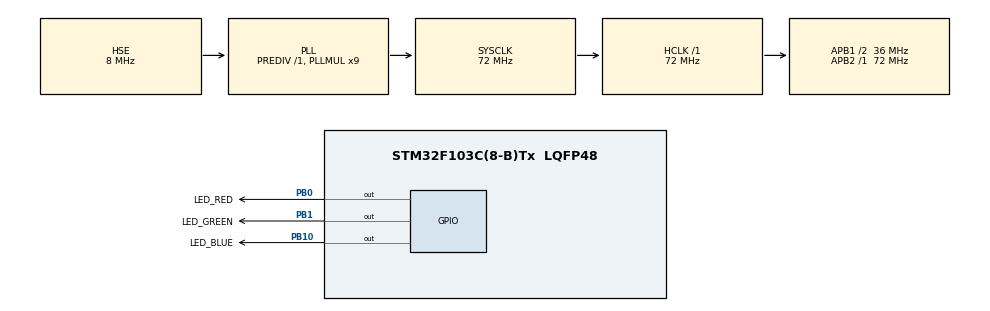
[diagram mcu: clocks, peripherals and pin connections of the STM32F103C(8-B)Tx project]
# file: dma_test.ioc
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Dma.MEMTOMEM.0.Direction=DMA_MEMORY_TO_MEMORY
Dma.MEMTOMEM.0.Instance=DMA1_Channel1
Dma.MEMTOMEM.0.MemDataAlignment=DMA_MDATAALIGN_BYTE
Dma.MEMTOMEM.0.MemInc=DMA_MINC_ENABLE
Dma.MEMTOMEM.0.Mode=DMA_NORMAL
Dma.MEMTOMEM.0.PeriphDataAlignment=DMA_PDATAALIGN_BYTE
Dma.MEMTOMEM.0.PeriphInc=DMA_PINC_ENABLE
Dma.MEMTOMEM.0.Priority=DMA_PRIORITY_LOW
Dma.Request0=MEMTOMEM
Mcu.Family=STM32F1
Mcu.Name=STM32F103C(8-B)Tx
Mcu.Package=LQFP48
NVIC.PriorityGroup=NVIC_PRIORITYGROUP_4
PA13.Mode=Serial_Wire
PA13.Signal=SYS_JTMS-SWDIO
PA14.Mode=Serial_Wire
PA14.Signal=SYS_JTCK-SWCLK
PB0.GPIO_Label=LED_RED
PB0.Signal=GPIO_Output
PB1.GPIO_Label=LED_GREEN
PB1.Signal=GPIO_Output
PB10.GPIO_Label=LED_BLUE
PB10.Signal=GPIO_Output
PD0-OSC_IN.Mode=HSE-External-Oscillator
PD0-OSC_IN.Signal=RCC_OSC_IN
PD1-OSC_OUT.Mode=HSE-External-Oscillator
PD1-OSC_OUT.Signal=RCC_OSC_OUT
ProjectManager.HeapSize=0x200
ProjectManager.StackSize=0x400
ProjectManager.TargetToolchain=CMake
RCC.AHBFreq_Value=72000000
RCC.APB1CLKDivider=RCC_HCLK_DIV2
RCC.APB1Freq_Value=36000000
RCC.APB1TimFreq_Value=72000000
RCC.APB2Freq_Value=72000000
RCC.APB2TimFreq_Value=72000000
RCC.HCLKFreq_Value=72000000
RCC.PLLMUL=RCC_PLL_MUL9
RCC.PLLSourceVirtual=RCC_PLLSOURCE_HSE
RCC.SYSCLKFreq_VALUE=72000000
RCC.SYSCLKSource=RCC_SYSCLKSOURCE_PLLCLK
RCC.USBFreq_Value=72000000
board=custom

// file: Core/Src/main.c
/* USER CODE BEGIN Header */
/**
  ******************************************************************************
  * @file           : main.c
  * @brief          : Main program body
  ******************************************************************************
  * @attention
  *
  * Copyright (c) 2025 STMicroelectronics.
  * All rights reserved.
  *
  * This software is licensed under terms that can be found in the LICENSE file
  * in the root directory of this software component.
  * If no LICENSE file comes with this software, it is provided AS-IS.
  *
  ******************************************************************************
  */
/* USER CODE END Header */
#include "main.h"
#include "dma.h"
#include "gpio.h"
#include "stm32f103xb.h"
#include "stm32f1xx_hal.h"
#include "stm32f1xx_hal_dma.h"
#include "stm32f1xx_hal_gpio.h"

/* USER CODE BEGIN Includes */

#include <stdint.h>
#include <string.h>

/* USER CODE END Includes */

/* USER CODE BEGIN PD */

#define DATA_LEN 10 // 传输数据长度

/* USER CODE END PD */

/* USER CODE BEGIN PV */

// 源数据（存于flash，用const和属性定位到只读区）
const uint8_t src_data[DATA_LEN] __attribute__((section(".rodata"))) = {0x01, 0x02, 0x03, 0x04, 0x05, 0x06, 0x07, 0x08, 0x09, 0x0A};
// 目标数据（存于SRAM）
uint8_t dest_data[DATA_LEN] = {0};

/* USER CODE END PV */

void SystemClock_Config(void);

int main(void)
{

  /* MCU Configuration--------------------------------------------------------*/

  /* Reset of all peripherals, Initializes the Flash interface and the Systick. */
  HAL_Init();

  /* Configure the system clock */
  SystemClock_Config();

  /* Initialize all configured peripherals */
  MX_GPIO_Init();
  MX_DMA_Init();
  /* USER CODE BEGIN 2 */

  // 配置dma传输参数
  HAL_DMA_Start(&hdma_memtomem_dma1_channel1, (uint32_t)src_data, (uint32_t)dest_data, DATA_LEN);

  // 等待dma传输完成
  HAL_DMA_PollForTransfer(&hdma_memtomem_dma1_channel1, HAL_DMA_FULL_TRANSFER, HAL_MAX_DELAY);

  // 数据比对
  uint8_t is_match = 1;
  for (int i = 0; i < DATA_LEN; i++) {
    if (src_data[i] != dest_data[i]) {
      is_match = 0;
      break;
    }
  }

  // RGB灯显示结果
  if (is_match) {
    // RGB彩灯亮
    HAL_GPIO_WritePin(GPIOB, GPIO_PIN_0, GPIO_PIN_SET);
    HAL_GPIO_WritePin(GPIOB, GPIO_PIN_1, GPIO_PIN_SET);
    HAL_GPIO_WritePin(GPIOB, GPIO_PIN_10, GPIO_PIN_SET);
  } else {
    // 不匹配红灯闪烁
    HAL_GPIO_TogglePin(GPIOB, GPIO_PIN_0);
    HAL_Delay(500);
  }

  /* USER CODE END 2 */

  /* Infinite loop */
  while (1)
  {

  }
}

void SystemClock_Config(void)
{
  RCC_OscInitTypeDef RCC_OscInitStruct = {0};
  RCC_ClkInitTypeDef RCC_ClkInitStruct = {0};

  /** Initializes the RCC Oscillators according to the specified parameters
  * in the RCC_OscInitTypeDef structure.
  */
  RCC_OscInitStruct.OscillatorType = RCC_OSCILLATORTYPE_HSE;
  RCC_OscInitStruct.HSEState = RCC_HSE_ON;
  RCC_OscInitStruct.HSEPredivValue = RCC_HSE_PREDIV_DIV1;
  RCC_OscInitStruct.HSIState = RCC_HSI_ON;
  RCC_OscInitStruct.PLL.PLLState = RCC_PLL_ON;
  RCC_OscInitStruct.PLL.PLLSource = RCC_PLLSOURCE_HSE;
  RCC_OscInitStruct.PLL.PLLMUL = RCC_PLL_MUL9;
  if (HAL_RCC_OscConfig(&RCC_OscInitStruct) != HAL_OK)
  {
    Error_Handler();
  }

  /** Initializes the CPU, AHB and APB buses clocks
  */
  RCC_ClkInitStruct.ClockType = RCC_CLOCKTYPE_HCLK|RCC_CLOCKTYPE_SYSCLK
                              |RCC_CLOCKTYPE_PCLK1|RCC_CLOCKTYPE_PCLK2;
  RCC_ClkInitStruct.SYSCLKSource = RCC_SYSCLKSOURCE_PLLCLK;
  RCC_ClkInitStruct.AHBCLKDivider = RCC_SYSCLK_DIV1;
  RCC_ClkInitStruct.APB1CLKDivider = RCC_HCLK_DIV2;
  RCC_ClkInitStruct.APB2CLKDivider = RCC_HCLK_DIV1;

  if (HAL_RCC_ClockConfig(&RCC_ClkInitStruct, FLASH_LATENCY_2) != HAL_OK)
  {
    Error_Handler();
  }
}

void Error_Handler(void)
{
  /* USER CODE BEGIN Error_Handler_Debug */
  /* User can add his own implementation to report the HAL error return state */
  __disable_irq();
  while (1)
  {
    // 进入错误处理状态，红灯亮
    HAL_GPIO_WritePin(GPIOB, GPIO_PIN_0, GPIO_PIN_SET);
  }
  /* USER CODE END Error_Handler_Debug */
}
